# A31T41x register map
Vendor: ABOV Semiconductor Co., Ltd.; File version: 1.0
ARM Cortex-M0 32-bit MCU, CPU clock up to 48MHz, etc.
CPU: CM0PLUS r0p1, little endian, no MPU, no FPU, VTOR, vendor SysTick, 2 interrupt priority bits
Registers are 32-bit, read-write, reset 0x0 unless marked. A register's access mark holds for its fields unless they carry their own. Offsets are from the block's base; lines under a group give offsets from that group; [hi:lo] are bit positions; {n}, {i} and the like mark numbered series; 'fields as' and 'values as' point back to an identical list; <NAME> marks a mode.

## Memory map
0x40000000 SCU size 0x100 — System Control Unit
0x40000200 WDT size 0x100 — WATCH-DOG TIMER
0x40000400 DMA0 size 0x10
0x40000410 DMA1 size 0x10
0x40000420 DMA2 size 0x10
0x40000430 DMA3 size 0x10
0x40000600 FRT size 0x100 — Free Run Timer
0x40001000 USART size 0x100 — USART 10 (UART + SPI)
0x40001100 USART11 size 0x100
0x40001200 USART12 size 0x100
0x40003000 TIMER0 size 0x40
0x40003040 TIMER1 size 0x40
0x40003080 TIMER2 size 0x40
0x400030C0 TIMER3 size 0x40
0x40003100 TIMER4 size 0x40
0x40004000 HSICMU size 0x20 — HIGH-SPEED INTERNAL OSC CLOCK MANAGEMENT UNIT
0x4000A000 I2C0 size 0x100
0x4000A100 I2C1 size 0x100
0x4000A200 I2C2 size 0x100
0x4000B380 CMP size 0x100 — Comparator
0x4000F000 CHIPCONFIG size 0x20 — Chip Configuration Data
0x4000F020 DBGMCU size 0x10 — Debug MCU Control Register
0x40080000 CFMC size 0x1000 — CODE FLASH MEMORY CONTROLLER
0x40082000 CRC size 0x1000 — Cyclic Redundancy Check calculation module
0x40090000 PA size 0x100
0x40090100 PB size 0x100
0x40090200 PC size 0x100
0x40090300 PD size 0x100
0x40090400 PE size 0x100
0x40090500 PF size 0x100
0x40090F0C PORTRSTDBCR size 0x40 — General Port Reset Debounce Enable
0x40090FF0 PORTEN size 0x10 — General Port Access Enable
0x40092000 ADC size 0x100 — 12-BIT A/D CONVERTER
0x50000400 DMA size 0x10 — Direct Memory Access Control 0
0x50001000 USART10 size 0x100
0x50003000 TIMER size 0x40 — TIMER COUNTER 0
0x5000A000 I2C size 0x100 — Inter-Integrated Circuit
0x50090000 PCU size 0x100 — General Port

## Interrupts
0 LVI (SCU)
1 SYSCLKFAIL (SCU)
3 LSEFAIL (SCU)
4 WDT
5 FRT
6 CFMC
7 TIMER0
8 TIMER1
9 TIMER2
10 TIMER3
11 GPIOAB (PA, PB)
12 GPIOCD (PC, PD)
13 GPIOEF (PE, PF)
14 TIMER4
16 USART10
17 USART11
18 USART12
19 I2C0
22 ADC
23 CRC
24 CMP0 (CMP)
25 CMP1 (CMP)
26 I2C1
27 I2C2

## CHIPCONFIG — Chip Configuration Data
Base 0x4000F000
0x00 VENDID ro reset 0x41424F56 — Vendor identification bits
0x04 CHIPID ro reset 0x54314130 — Chip ID bits
0x08 DEVID 8-bit ro reset 0x306900 — Device ID Register
0x10 REVNO 8-bit ro — Chip revision number

## PCU — General Port
Base 0x50090000
Same registers: PA 0x40090000, PB 0x40090100, PC 0x40090200, PD 0x40090300, PE 0x40090400, PF 0x40090500
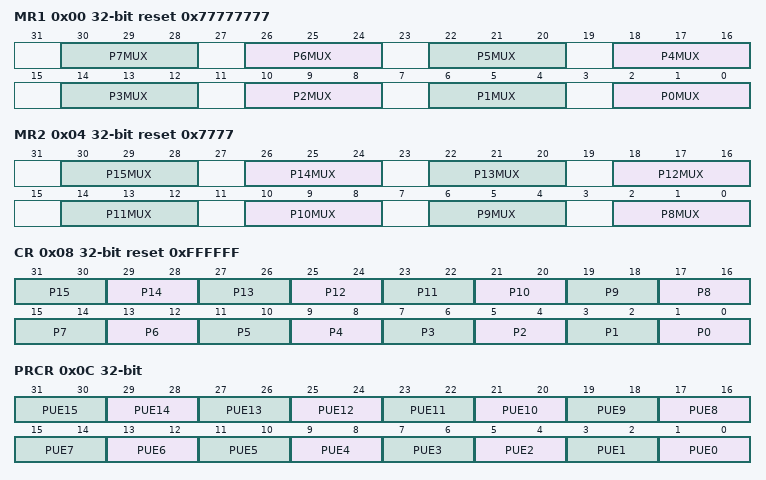
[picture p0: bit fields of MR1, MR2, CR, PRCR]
0x00 MR1 reset 0x77777777 — Port n MUX1 Selection Register
  [4n+2:4n] P{n}MUX (n=0..7) — Pin {n} Mode Selection bits
0x04 MR2 reset 0x7777 — Port n MUX2 Selection Register
  [4n-30:4n-32] P{n}MUX (n=8..15) — Pin {n} Mode Selection bits
0x08 CR reset 0xFFFFFF — Port n Type Selection Register
  [2n+1:2n] P{n} (n=0..15) — Pin {n} Type Selection bit
0x0C PRCR — Port n Pull-up/down Selection Register
  [2n+1:2n] PUE{n} (n=0..15) — Pin {n} Pull-up/down Selection bits
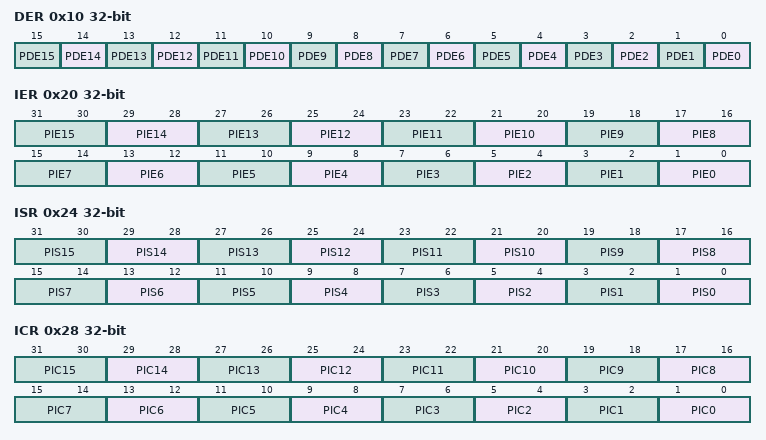
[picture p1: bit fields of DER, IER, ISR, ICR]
0x10 DER — Port n Debounce Enable Register
  [n] PDE{n} (n=0..15) — Pin {n} Debounce Enable bits
0x20 IER — Port n Interrupt Enable Register
  [2n+1:2n] PIE{n} (n=0..15) — Pin {n} Interrupt Enable bit
0x24 ISR — Port n Interrupt Status Register
  [2n+1:2n] PIS{n} (n=0..15) — Pin {n} Interrupt Status bit
0x28 ICR — Port n Interrupt Control Register
  [2n+1:2n] PIC{n} (n=0..15) — Pin {n} Interrupt Control bit
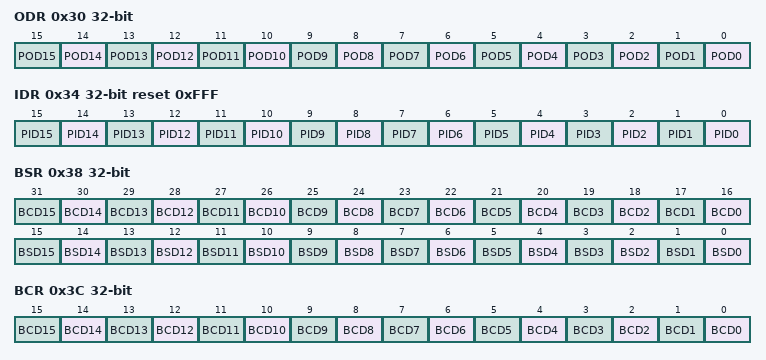
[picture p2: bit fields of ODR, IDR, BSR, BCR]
0x30 ODR — Port n Output Data Register
  [n] POD{n} (n=0..15) — Pin {n} Output data bit
0x34 IDR ro reset 0xFFF — Port n Input Data Register
  [n] PID{n} rw (n=0..15) — Pin {n} Input data bit
0x38 BSR wo — Port n Bit Set/Clear Register
  [n+16] BCD{n} (n=0..15) — Port {n} Bit Clear bits
  [n] BSD{n} (n=0..15) — Port {n} Bit Set bits
0x3C BCR wo — Port n Bit Reset Register
  [n] BCD{n} (n=0..15) — Port {n} Bit Clear bits
